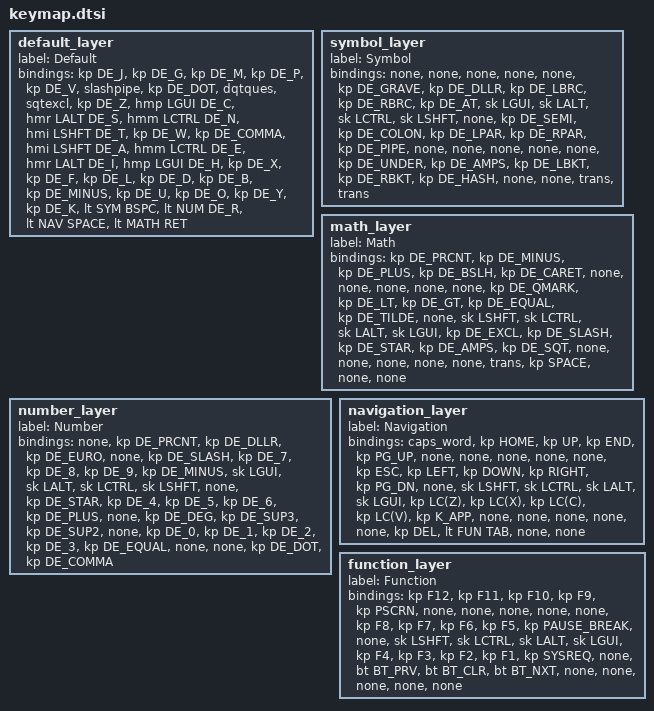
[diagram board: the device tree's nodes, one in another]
default_layer {
	label = "Default";
	bindings = <
	// --------------+---------------+---------------+---------------+--------------||---------------+---------------+---------------+---------------+---------------|
		&kp DE_J		&kp DE_G		&kp DE_M		&kp DE_P		&kp DE_V		&slashpipe		&kp DE_DOT		&dqtques		&sqtexcl 		&kp DE_Z
	// --------------+---------------+---------------+---------------+--------------||---------------+---------------+---------------+---------------+---------------|
		&hmp LGUI DE_C	&hmr LALT DE_S	&hmm LCTRL DE_N	&hmi LSHFT DE_T	&kp DE_W		&kp DE_COMMA	&hmi LSHFT DE_A	&hmm LCTRL DE_E &hmr LALT DE_I	&hmp LGUI DE_H
	// --------------+---------------+---------------+---------------+--------------||---------------+---------------+---------------+---------------+---------------|
		&kp DE_X		&kp DE_F		&kp DE_L		&kp DE_D		&kp DE_B		&kp DE_MINUS   	&kp DE_U		&kp DE_O		&kp DE_Y		&kp DE_K	
	// --------------+---------------+---------------+---------------+--------------||---------------+---------------+---------------+---------------+---------------|
														&lt SYM BSPC	&lt NUM DE_R	&lt NAV SPACE	&lt MATH RET
							        				//---------------+--------------||---------------+---------------|
	>;
};

symbol_layer {
	label = "Symbol";
	bindings = <
	// --------------+---------------+---------------+---------------+--------------||---------------+---------------+---------------+---------------+---------------|
		&none			&none			&none			&none			&none			&kp DE_GRAVE	&kp DE_DLLR		&kp DE_LBRC		&kp DE_RBRC		&kp DE_AT 
	// --------------+---------------+---------------+---------------+--------------||---------------+---------------+---------------+---------------+---------------|
		&sk LGUI		&sk LALT		&sk LCTRL		&sk LSHFT		&none			&kp DE_SEMI		&kp DE_COLON	&kp DE_LPAR		&kp DE_RPAR		&kp DE_PIPE
	// --------------+---------------+---------------+---------------+--------------||---------------+---------------+---------------+---------------+---------------|
		&none			&none			&none			&none			&none			&kp DE_UNDER	&kp DE_AMPS		&kp DE_LBKT 	&kp DE_RBKT		&kp DE_HASH
	// --------------+---------------+---------------+---------------+--------------||---------------+---------------+---------------+---------------+---------------|
														&none			&none	 		&trans 			&trans
							        				//---------------+--------------||---------------+---------------|
	>;
};


math_layer {
	label = "Math";
	bindings = <
	// --------------+---------------+---------------+---------------+--------------||---------------+---------------+---------------+---------------+---------------|
		&kp DE_PRCNT	&kp DE_MINUS	&kp DE_PLUS		&kp DE_BSLH		&kp DE_CARET	&none			&none			&none			&none			&none 
	// --------------+---------------+---------------+---------------+--------------||---------------+---------------+---------------+---------------+---------------|
		&kp DE_QMARK	&kp DE_LT		&kp DE_GT		&kp DE_EQUAL	&kp DE_TILDE	&none			&sk LSHFT		&sk LCTRL		&sk LALT		&sk LGUI
	// --------------+---------------+---------------+---------------+--------------||---------------+---------------+---------------+---------------+---------------|
		&kp DE_EXCL		&kp DE_SLASH	&kp DE_STAR		&kp DE_AMPS		&kp DE_SQT		&none			&none			&none			&none			&none			
	// --------------+---------------+---------------+---------------+--------------||---------------+---------------+---------------+---------------+---------------|
														&trans			&kp SPACE		&none 			&none
							        				//---------------+--------------||---------------+---------------|
	>;
};

number_layer {
	label = "Number";
	bindings = <
	// --------------+---------------+---------------+---------------+--------------||---------------+---------------+---------------+---------------+---------------|
		&none			&kp DE_PRCNT	&kp DE_DLLR		&kp DE_EURO		&none			&kp DE_SLASH	&kp DE_7		&kp DE_8		&kp DE_9		&kp DE_MINUS 
	// --------------+---------------+---------------+---------------+--------------||---------------+---------------+---------------+---------------+---------------|
		&sk LGUI		&sk LALT		&sk LCTRL		&sk LSHFT		&none			&kp DE_STAR		&kp DE_4		&kp DE_5		&kp DE_6		&kp DE_PLUS
	// --------------+---------------+---------------+---------------+--------------||---------------+---------------+---------------+---------------+---------------|
		&none			&kp DE_DEG		&kp DE_SUP3		&kp DE_SUP2		&none			&kp DE_0	   	&kp DE_1		&kp DE_2		&kp DE_3		&kp DE_EQUAL	
	// --------------+---------------+---------------+---------------+--------------||---------------+---------------+---------------+---------------+---------------|
														&none			&none			&kp DE_DOT		&kp DE_COMMA
							            			//---------------+--------------||---------------+---------------|
	>;
};

navigation_layer {
	label = "Navigation";
	bindings = <
	// --------------+---------------+---------------+---------------+--------------||---------------+---------------+---------------+---------------+---------------|
		&caps_word		&kp HOME		&kp UP			&kp END			&kp PG_UP		&none			&none			&none			&none			&none 
	// --------------+---------------+---------------+---------------+--------------||---------------+---------------+---------------+---------------+---------------|
		&kp ESC 		&kp LEFT		&kp DOWN		&kp RIGHT		&kp PG_DN		&none			&sk LSHFT		&sk LCTRL 		&sk LALT		&sk LGUI
	// --------------+---------------+---------------+---------------+--------------||---------------+---------------+---------------+---------------+---------------|
		&kp LC(Z)		&kp LC(X)		&kp LC(C)		&kp LC(V)		&kp K_APP		&none	    	&none			&none			&none			&none	
	// --------------+---------------+---------------+---------------+--------------||---------------+---------------+---------------+---------------+---------------|
														&kp DEL			&lt FUN TAB		&none			&none
							        				//---------------+--------------||---------------+---------------|
	>;
};

function_layer {
	label = "Function";
	bindings = <
	// --------------+---------------+---------------+---------------+--------------||---------------+---------------+---------------+---------------+---------------|
		&kp F12			&kp F11			&kp F10			&kp F9	 		&kp PSCRN 		&none			&none			&none			&none			&none		
	// --------------+---------------+---------------+---------------+--------------||---------------+---------------+---------------+---------------+---------------|
		&kp F8			&kp F7 			&kp F6			&kp F5			&kp PAUSE_BREAK	&none 			&sk LSHFT		&sk LCTRL		&sk LALT		&sk LGUI		
	// --------------+---------------+---------------+---------------+--------------||---------------+---------------+---------------+---------------+---------------|
		&kp F4			&kp F3			&kp F2			&kp F1			&kp SYSREQ		&none			&bt BT_PRV		&bt BT_CLR		&bt BT_NXT 		&none		
	// --------------+---------------+---------------+---------------+--------------||---------------+---------------+---------------+---------------+---------------|
														&none			&none			&none			&none
							            			//---------------+--------------||---------------+---------------|
	>;
};
